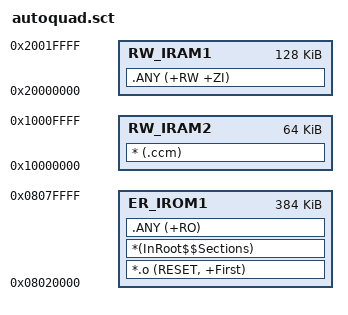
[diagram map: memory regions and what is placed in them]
; *************************************************************
; *** Scatter-Loading Description File generated by uVision ***
; *************************************************************

LR_IROM1 0x08020000 0x0060000  {    ; load region size_region
  ER_IROM1 0x08020000 0x0060000  {  ; load address = execution address
   *.o (RESET, +First)
   *(InRoot$$Sections)
   .ANY (+RO)
  }
  RW_IRAM1 0x20000000 0x00020000  {  ; RW data
   .ANY (+RW +ZI)
  }
  RW_IRAM2 0x10000000 0x00010000  {
   * (.ccm)
  }
  
 ; ARM_LIB_STACK 0x10010000 EMPTY -0x00000400 {}
}

